# K32W061 register map
Vendor: nxp.com; File version: 1.0
CPU: CM4 r0p1, little endian, MPU, no FPU, VTOR, 3 interrupt priority bits
Registers are 32-bit, read-write, reset 0x0 unless marked. A register's access mark holds for its fields unless they carry their own. Offsets are from the block's base; [hi:lo] are bit positions; {n}, {i} and the like mark numbered series; 'fields as' and 'values as' point back to an identical list.

## SYSCON (part 1 of 2) — This is the description of component syscon. It is the System Control APB bus interface. More details will follow.
Base 0x40000000
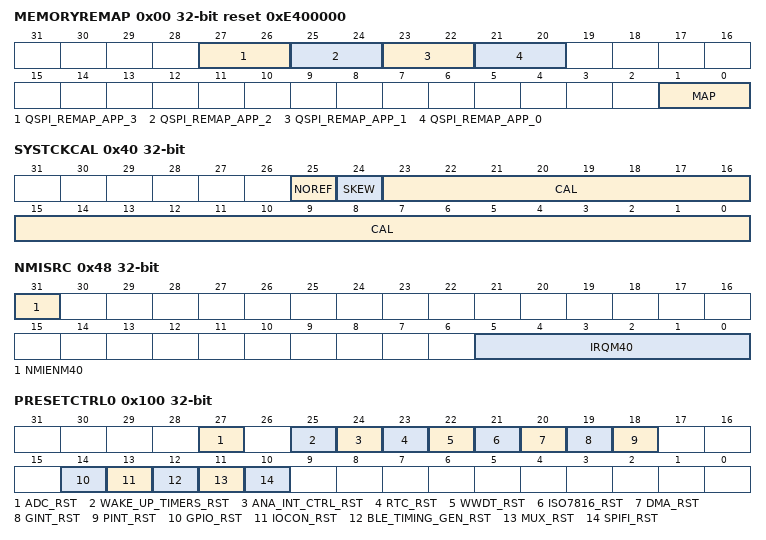
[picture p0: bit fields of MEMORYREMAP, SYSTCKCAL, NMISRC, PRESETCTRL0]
0x00 MEMORYREMAP reset 0xE400000 — Memory Remap control register
  [27:26] QSPI_REMAP_APP_3 — Address bits to use when QSPI Flash address [19:18] = 3 (256-KB unit page). Setting 11 gives no remapping.
  [25:24] QSPI_REMAP_APP_2 — Address bits to use when QSPI Flash address [19:18] = 2 (256-KB unit page). Setting 10 gives no remapping.
  [23:22] QSPI_REMAP_APP_1 — Address bits to use when QSPI Flash address [19:18] = 1 (256-KB unit page). Setting 01 gives no remapping.
  [21:20] QSPI_REMAP_APP_0 — Address bits to use when QSPI Flash address [19:18] = 0 (256-KB unit page). Setting 00 gives no remapping.
  [1:0] MAP — Select the location of the vector table : 0: Vector Table in ROM. 1: Vector Table in RAM. 2: Vector Table in Flash. 3: Vector Table in Flash.
0x10 AHBMATPRIO — AHB Matrix priority control register
0x40 SYSTCKCAL — System tick counter calibration
  [25] NOREF — Cortex System tick timer SYST_CALIB.NOREF setting. When 0, a separate reference clock is available. When 1, a separate reference clock is not available.
  [24] SKEW — Cortex System tick timer SYST_CALIB.SKEW setting. When 0, the value of SYST_CALIB.TENMS field is considered to be precise. When 1, the value of TENMS is not considered to be precise.
  [23:0] CAL — Cortex System tick timer calibration value, readable from Cortex SYST_CALIB.TENMS register field. Set this value to be the number of clock periods to give 10ms period. SYSTICK freq is a function of the mainclk and SYSTICKCLKDIV register. If the tick timer is configured to use the System clock directly then this value must reflect the 10ms tick count for that clock.
0x48 NMISRC — NMI Source Select
  [31] NMIENM40 — Write a 1 to this bit to enable the Non-Maskable Interrupt (NMI) source selected by IRQM40. The NMI Interrupt should be disabled before changing the source selection (IRQM40)
  [5:0] IRQM40 — The number of the interrupt source within the interrupt array that acts as the Non-Maskable Interrupt (NMI) for the Cortex-M4, if enabled by NMIENM40. This can also cause the device to wakeup from sleep.
0x4C ASYNCAPBCTRL — Asynchronous APB Control
  [0] ENABLE — Enables the asynchronous APB bridge and subsystem
0x100 PRESETCTRL0 (PRESETCTRL view) — Peripheral reset control 0
  [27] ADC_RST — ADC reset control. 0: Clear reset to this function. 1: Assert reset to this function.
  [25] WAKE_UP_TIMERS_RST — Wake up Timers reset control. 0: Clear reset to this function. 1: Assert reset to this function. This will clear interrupt status flag. However, configuration for wake timers that is in SYSCON will not be reset, these should be managed through the SYSCON regsiters.
  [24] ANA_INT_CTRL_RST — Analog Modules Interrupt Controller reset control. 0: Clear reset to this function. 1: Assert reset to this function.
  [23] RTC_RST — Real Time Clock (RTC) reset control. 0: Clear reset to this function. 1: Assert reset to this function.
  [22] WWDT_RST — Watchdog Timer reset control. 0: Clear reset to this function. 1: Assert reset to this function.
  [21] ISO7816_RST — ISO7816 reset control. 0: Clear reset to this function. 1: Assert reset to this function.
  [20] DMA_RST — DMA reset control. 0: Clear reset to this function. 1: Assert reset to this function.
  [19] GINT_RST — Group interrupt (GINT) reset control. 0: Clear reset to this function. 1: Assert reset to this function.
  [18] PINT_RST — Pin interrupt (PINT) reset control. 0: Clear reset to this function. 1: Assert reset to this function.
  [14] GPIO_RST — GPIO reset control. 0: Clear reset to this function. 1: Assert reset to this function.
  [13] IOCON_RST — I/O controller reset control. 0: Clear reset to this function. 1: Assert reset to this function.
  [12] BLE_TIMING_GEN_RST — BLE Low Power Control module reset. 0: Clear reset to this function. 1: Assert reset to this function.
  [11] MUX_RST — Input Mux reset control. 0: Clear reset to this function. 1: Assert reset to this function.
  [10] SPIFI_RST — Quad SPI Flash controller reset control. 0: Clear reset to this function. 1: Assert reset to this function.
0x100 PRESETCTRLS0 reset 0xFFFFFFFF (PRESETCTRL view) — Pin assign register
  [31:0] DATA
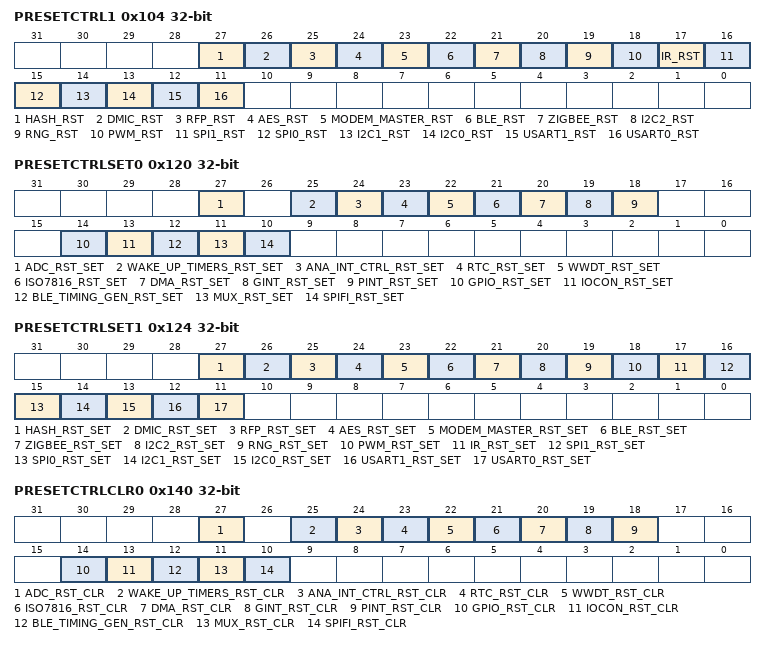
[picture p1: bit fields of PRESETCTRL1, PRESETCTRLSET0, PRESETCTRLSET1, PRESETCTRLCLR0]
0x104 PRESETCTRL1 (PRESETCTRL view) — Peripheral reset control 1
  [27] HASH_RST — HASH reset control. 0: Clear reset to this function. 1: Assert reset to this function.
  [26] DMIC_RST — DMIC Reset control. 0: Clear reset to this function. 1: Assert reset to this function.
  [25] RFP_RST — RFP (Radio controller) reset control. 0: Clear reset to this function. 1: Assert reset to this function.
  [24] AES_RST — AES256 reset control. 0: Clear reset to this function. 1: Assert reset to this function.
  [23] MODEM_MASTER_RST — MODEM AHB Master Interface reset control. 0: Clear reset to this function. 1: Assert reset to this function.
  [22] BLE_RST — BLE reset control. 0: Clear reset to this function. 1: Assert reset to this function.
  [21] ZIGBEE_RST — Zigbee reset control. 0: Clear reset to this function. 1: Assert reset to this function.
  [20] I2C2_RST — I2C2 reset control. 0: Clear reset to this function. 1: Assert reset to this function.
  [19] RNG_RST — Random Number Generator reset control. 0: Clear reset to this function. 1: Assert reset to this function.
  [18] PWM_RST — PWM reset control. 0: Clear reset to this function. 1: Assert reset to this function.
  [17] IR_RST — Infra Red reset control. 0: Clear reset to this function. 1: Assert reset to this function.
  [16] SPI1_RST — SPI1 reset control. 0: Clear reset to this function. 1: Assert reset to this function.
  [15] SPI0_RST — SPI0 reset control. 0: Clear reset to this function. 1: Assert reset to this function.
  [14] I2C1_RST — I2C1 reset control. 0: Clear reset to this function. 1: Assert reset to this function.
  [13] I2C0_RST — I2C0 reset control. 0: Clear reset to this function. 1: Assert reset to this function.
  [12] USART1_RST — UART1 reset control. 0: Clear reset to this function. 1: Assert reset to this function.
  [11] USART0_RST — UART0 reset control. 0: Clear reset to this function. 1: Assert reset to this function.
0x104 PRESETCTRLS1 reset 0xFFFFFFFF (PRESETCTRL view) — Pin assign register
  [31:0] DATA
0x120 PRESETCTRLSET0 reset not defined (PRESETCTRLSET view) — Set bits in PRESETCTRL0. It is recommended that changes to PRESETCTRL registers be accomplished by using the related PRESETCTRLSET and PRESETCTRLCLR registers.
  [27] ADC_RST_SET wo — Writing one to this register sets the ADC_RST bit in the PRESETCTRL0 register
  [25] WAKE_UP_TIMERS_RST_SET wo — Writing one to this register sets the WAKE_UP_TIMERS bit in the PRESETCTRL0 register
  [24] ANA_INT_CTRL_RST_SET wo — Writing one to this register sets the ANA_INT_CTRL_RST bit in the PRESETCTRL0 register
  [23] RTC_RST_SET wo — Writing one to this register sets the RTC_RST bit in the PRESETCTRL0 register
  [22] WWDT_RST_SET wo — Writing one to this register sets the WWDT_RST bit in the PRESETCTRL0 register
  [21] ISO7816_RST_SET wo — Writing one to this register sets the ISO7816_RST bit in the PRESETCTRL0 register
  [20] DMA_RST_SET wo — Writing one to this register sets the DMA_RST bit in the PRESETCTRL0 register
  [19] GINT_RST_SET wo — Writing one to this register sets the GINT_RST bit in the PRESETCTRL0 register
  [18] PINT_RST_SET wo — Writing one to this register sets the PINT_RST bit in the PRESETCTRL0 register
  [14] GPIO_RST_SET wo — Writing one to this register sets the GPIO_RST bit in the PRESETCTRL0 register
  [13] IOCON_RST_SET wo — Writing one to this register sets the IOCON_RST bit in the PRESETCTRL0 register
  [12] BLE_TIMING_GEN_RST_SET wo — Writing one to this register sets the BLE_TIMING_GEN_RST bit in the PRESETCTRL0 register
  [11] MUX_RST_SET wo — Writing one to this register sets the MUX_RST bit in the PRESETCTRL0 register
  [10] SPIFI_RST_SET wo — Writing one to this register sets the SPIFI_RST bit in the PRESETCTRL0 register
0x120 PRESETCTRLSETS0 reset 0xFFFFFFFF (PRESETCTRLSET view) — Pin assign register
  [31:0] DATA
0x124 PRESETCTRLSET1 reset not defined (PRESETCTRLSET view) — Set bits in PRESETCTRL1. It is recommended that changes to PRESETCTRL registers be accomplished by using the related PRESETCTRLSET and PRESETCTRLCLR registers.
  [27] HASH_RST_SET wo — Writing one to this register sets the HASH_RST bit in the PRESETCTRL1 register
  [26] DMIC_RST_SET wo — Writing one to this register sets the DMIC_RST bit in the PRESETCTRL1 register
  [25] RFP_RST_SET wo — Writing one to this register sets the RFP_RST bit in the PRESETCTRL1 register
  [24] AES_RST_SET wo — Writing one to this register sets the AES_RST bit in the PRESETCTRL1 register
  [23] MODEM_MASTER_RST_SET wo — Writing one to this register sets the MODEM_MASTER_RST bit in the PRESETCTRL1 register
  [22] BLE_RST_SET wo — Writing one to this register sets the BLE_RST bit in the PRESETCTRL1 register
  [21] ZIGBEE_RST_SET wo — Writing one to this register sets the ZIGBEE_RST bit in the PRESETCTRL1 register
  [20] I2C2_RST_SET wo — Writing one to this register sets the I2C2_RST bit in the PRESETCTRL1 register
  [19] RNG_RST_SET wo — Writing one to this register sets the RNG_RST bit in the PRESETCTRL1 register
  [18] PWM_RST_SET wo — Writing one to this register sets the PWM_RST bit in the PRESETCTRL1 register
  [17] IR_RST_SET wo — Writing one to this register sets the IR_RST bit in the PRESETCTRL1 register
  [16] SPI1_RST_SET wo — Writing one to this register sets the SPI1_RST bit in the PRESETCTRL1 register
  [15] SPI0_RST_SET wo — Writing one to this register sets the SPI0_RST bit in the PRESETCTRL1 register
  [14] I2C1_RST_SET wo — Writing one to this register sets the I2C1_RST bit in the PRESETCTRL1 register
  [13] I2C0_RST_SET wo — Writing one to this register sets the I2C0_RST bit in the PRESETCTRL1 register
  [12] USART1_RST_SET wo — Writing one to this register sets the UART1_RST bit in the PRESETCTRL1 register
  [11] USART0_RST_SET wo — Writing one to this register sets the UART0_RST bit in the PRESETCTRL1 register
0x124 PRESETCTRLSETS1 reset 0xFFFFFFFF (PRESETCTRLSET view) — Pin assign register
  [31:0] DATA
0x140 PRESETCTRLCLR0 reset not defined (PRESETCTRLCLR view) — Clear bits in PRESETCTRL0. It is recommended that changes to PRESETCTRL registers be accomplished by using the related PRESETCTRLSET and PRESETCTRLCLR registers.
  [27] ADC_RST_CLR wo — Writing one to this register clears the ADC_RST bit in the PRESETCTRL0 register
  [25] WAKE_UP_TIMERS_RST_CLR wo — Writing one to this register clears the WAKE_UP_TIMERS_RST bit in the PRESETCTRL0 register
  [24] ANA_INT_CTRL_RST_CLR wo — Writing one to this register clears the ANA_INT_CTRL_RST bit in the PRESETCTRL0 register
  [23] RTC_RST_CLR wo — Writing one to this register clears the RTC_RST bit in the PRESETCTRL0 register
  [22] WWDT_RST_CLR wo — Writing one to this register clears the WWDT_RST bit in the PRESETCTRL0 register
  [21] ISO7816_RST_CLR wo — Writing one to this register clears the ISO7816_RST bit in the PRESETCTRL0 register
  [20] DMA_RST_CLR wo — Writing one to this register clears the DMA_RST bit in the PRESETCTRL0 register
  [19] GINT_RST_CLR wo — Writing one to this register clears the GINT_RST bit in the PRESETCTRL0 register
  [18] PINT_RST_CLR wo — Writing one to this register clears the PINT_RST bit in the PRESETCTRL0 register
  [14] GPIO_RST_CLR wo — Writing one to this register clears the GPIO_RST bit in the PRESETCTRL0 register
  [13] IOCON_RST_CLR wo — Writing one to this register clears the IOCON_RST bit in the PRESETCTRL0 register
  [12] BLE_TIMING_GEN_RST_CLR wo — Writing one to this register clears the BLE_TIMING_GEN_RST bit in the PRESETCTRL0 register
  [11] MUX_RST_CLR wo — Writing one to this register clears the MUX_RST bit in the PRESETCTRL0 register
  [10] SPIFI_RST_CLR wo — Writing one to this register clears the SPIFI_RST bit in the PRESETCTRL0 register
0x140 PRESETCTRLCLRS0 reset 0xFFFFFFFF (PRESETCTRLCLR view) — Pin assign register
  [31:0] DATA
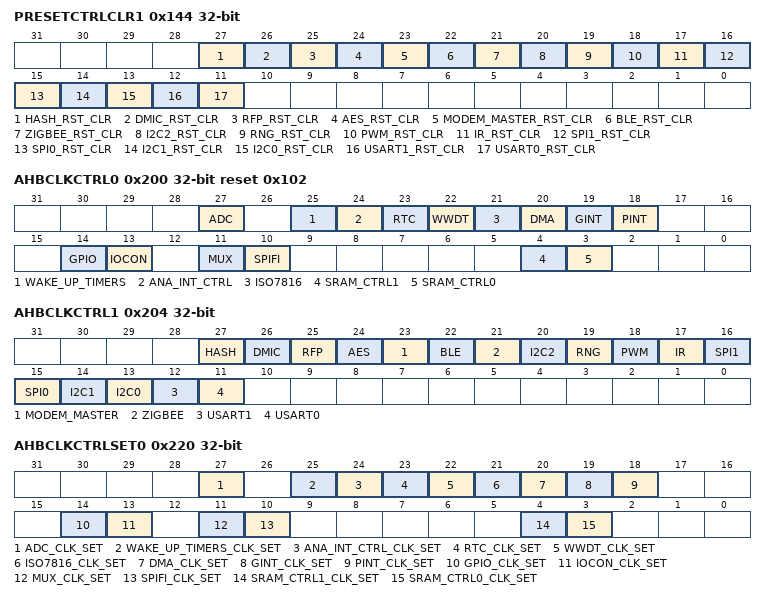
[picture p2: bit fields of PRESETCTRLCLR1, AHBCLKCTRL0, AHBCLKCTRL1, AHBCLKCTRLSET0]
0x144 PRESETCTRLCLR1 reset not defined (PRESETCTRLCLR view) — Clear bits in PRESETCTRL1. It is recommended that changes to PRESETCTRL registers be accomplished by using the related PRESETCTRLSET and PRESETCTRLCLR registers.
  [27] HASH_RST_CLR wo — Writing one to this register clears the HASH_RST bit in the PRESETCTRL1 register
  [26] DMIC_RST_CLR wo — Writing one to this register clears the DMIC_RST bit in the PRESETCTRL1 register
  [25] RFP_RST_CLR wo — Writing one to this register clears the RFP_RST bit in the PRESETCTRL1 register
  [24] AES_RST_CLR wo — Writing one to this register clears the AES_RST bit in the PRESETCTRL1 register
  [23] MODEM_MASTER_RST_CLR wo — Writing one to this register clears the MODEM_MASTER_RST bit in the PRESETCTRL1 register
  [22] BLE_RST_CLR wo — Writing one to this register clears the BLE_RST bit in the PRESETCTRL1 register
  [21] ZIGBEE_RST_CLR wo — Writing one to this register clears the ZIGBEE_RST bit in the PRESETCTRL1 register
  [20] I2C2_RST_CLR wo — Writing one to this register clears the I2C2_RST bit in the PRESETCTRL1 register
  [19] RNG_RST_CLR wo — Writing one to this register clears the RNG_RST bit in the PRESETCTRL1 register
  [18] PWM_RST_CLR wo — Writing one to this register clears the PWM_RST bit in the PRESETCTRL1 register
  [17] IR_RST_CLR wo — Writing one to this register clears the IR_RST bit in the PRESETCTRL1 register
  [16] SPI1_RST_CLR wo — Writing one to this register clears the SPI1_RST bit in the PRESETCTRL1 register
  [15] SPI0_RST_CLR wo — Writing one to this register clears the SPI0_RST bit in the PRESETCTRL1 register
  [14] I2C1_RST_CLR wo — Writing one to this register clears the I2C1_RST bit in the PRESETCTRL1 register
  [13] I2C0_RST_CLR wo — Writing one to this register clears the I2C0_RST bit in the PRESETCTRL1 register
  [12] USART1_RST_CLR wo — Writing one to this register clears the UART1_RST bit in the PRESETCTRL1 register
  [11] USART0_RST_CLR wo — Writing one to this register clears the UART0_RST bit in the PRESETCTRL1 register
0x144 PRESETCTRLCLRS1 reset 0xFFFFFFFF (PRESETCTRLCLR view) — Pin assign register
  [31:0] DATA
0x200 AHBCLKCTRL0 reset 0x102 (AHBCLKCTRL view) — AHB Clock control 0
  [27] ADC — Enables the clock for the ADC Controller. 0: Disable. 1: Enable.
  [25] WAKE_UP_TIMERS — Enables the clock for the Wake up Timers. 0: Disable. 1: Enable.
  [24] ANA_INT_CTRL — Enables the clock for the Analog Interrupt Control module (for BOD and comparator status and interrupt control). 0: Disable. 1: Enable.
  [23] RTC — Enables the clock for the RTC. 0: Disable. 1: Enable.
  [22] WWDT — Enables the clock for the Watchdog Timer. 0: Disable. 1: Enable.
  [21] ISO7816 — Enables the clock for the ISO7816 smart card interface. 0: Disable. 1: Enable.
  [20] DMA — Enables the clock for the DMA controller. 0: Disable. 1: Enable.
  [19] GINT — Enables the clock for the Group interrupt block (GINT). 0: Disable. 1: Enable.
  [18] PINT — Enables the clock for the Pin interrupt block (PINT). 0: Disable. 1: Enable.
  [14] GPIO — Enables the clock for the GPIO. 0: Disable. 1: Enable.
  [13] IOCON — Enables the clock for the I/O controller block. 0: Disable. 1: Enable.
  [11] MUX — Enables the clock for the Input Mux. 0: Disable. 1: Enable.
  [10] SPIFI — Enables the clock for the Quad SPI Flash controller [Note: SPIFI IOs need configuring for high drive]. 0: Disable. 1: Enable.
  [4] SRAM_CTRL1 — Enables the clock for the SRAM Controller 1 (SRAM 8 to SRAM 11). 0: Disable. 1: Enable.
  [3] SRAM_CTRL0 — Enables the clock for the SRAM Controller 0 (SRAM 0 to SRAM 7). 0: Disable. 1: Enable.
0x200 AHBCLKCTRLS0 reset 0xFFFFFFFF (AHBCLKCTRL view) — Pin assign register
  [31:0] DATA
0x204 AHBCLKCTRL1 (AHBCLKCTRL view) — AHB Clock control 1
  [27] HASH — Enable the clock for the Hash. 0: Disable. 1: Enable.
  [26] DMIC — Enable the clock for the DMIC. 0: Disable. 1: Enable.
  [25] RFP — Enable the clock for the RFP (Radio Front End controller). 0: Disable. 1: Enable.
  [24] AES — Enable the clock for the AES. 0: Disable. 1: Enable.
  [23] MODEM_MASTER — Enable the clock for the Modem AHB Master Interface. 0: Disable. 1: Enable.
  [22] BLE — Enable the clock for the BLE Modem. 0: Disable. 1: Enable.
  [21] ZIGBEE — Enable the clock for the Zigbee Modem . 0: Disable. 1: Enable.
  [20] I2C2 — Enable the clock for the I2C2. 0: Disable. 1: Enable.
  [19] RNG — Enable the clock for the Random Number Generator. 0: Disable. 1: Enable.
  [18] PWM — Enable the clock for the PWM. 0: Disable. 1: Enable.
  [17] IR — Enable the clock for the Infra Red. 0: Disable. 1: Enable.
  [16] SPI1 — Enable the clock for the SPI1. 0: Disable. 1: Enable.
  [15] SPI0 — Enable the clock for the SPI0. 0: Disable. 1: Enable.
  [14] I2C1 — Enable the clock for the I2C1. 0: Disable. 1: Enable.
  [13] I2C0 — Enable the clock for the I2C0. 0: Disable. 1: Enable.
  [12] USART1 — Enable the clock for the UART1. 0: Disable. 1: Enable.
  [11] USART0 — Enable the clock for the UART0. 0: Disable. 1: Enable.
0x204 AHBCLKCTRLS1 reset 0xFFFFFFFF (AHBCLKCTRL view) — Pin assign register
  [31:0] DATA
0x220 AHBCLKCTRLSET0 reset not defined (AHBCLKCTRLSET view) — Set bits in AHBCLKCTRL0
  [27] ADC_CLK_SET wo — Writing one to this register sets the ADC bit in the AHBCLKCTRL0 register.
  [25] WAKE_UP_TIMERS_CLK_SET wo — Writing one to this register sets the WAKE_UP_TIMERS bit in the AHBCLKCTRL0 register.
  [24] ANA_INT_CTRL_CLK_SET wo — Writing one to this register sets the ANA_INT_CTRL bit in the AHBCLKCTRL0 register.
  [23] RTC_CLK_SET wo — Writing one to this register sets the RTC bit in the AHBCLKCTRL0 register.
  [22] WWDT_CLK_SET wo — Writing one to this register sets the WWDT bit in the AHBCLKCTRL0 register.
  [21] ISO7816_CLK_SET wo — Writing one to this register sets the ISO7816 bit in the AHBCLKCTRL0 register.
  [20] DMA_CLK_SET wo — Writing one to this register sets the DMA bit in the AHBCLKCTRL0 register.
  [19] GINT_CLK_SET wo — Writing one to this register sets the GINT bit in the AHBCLKCTRL0 register.
  [18] PINT_CLK_SET wo — Writing one to this register sets the PINT bit in the AHBCLKCTRL0 register.
  [14] GPIO_CLK_SET wo — Writing one to this register sets the GPIO bit in the AHBCLKCTRL0 register.
  [13] IOCON_CLK_SET wo — Writing one to this register sets the IOCON bit in the AHBCLKCTRL0 register.
  [11] MUX_CLK_SET wo — Writing one to this register sets the MUX bit in the AHBCLKCTRL0 register.
  [10] SPIFI_CLK_SET wo — Writing one to this register sets the SPIFI bit in the AHBCLKCTRL0 register.
  [4] SRAM_CTRL1_CLK_SET wo — Writing one to this register sets the SRAM_CTRL1 bit in the AHBCLKCTRL0 register.
  [3] SRAM_CTRL0_CLK_SET wo — Writing one to this register sets the SRAM_CTRL0 bit in the AHBCLKCTRL0 register.
0x220 AHBCLKCTRLSETS0 reset 0xFFFFFFFF (AHBCLKCTRLSET view) — Pin assign register
  [31:0] DATA
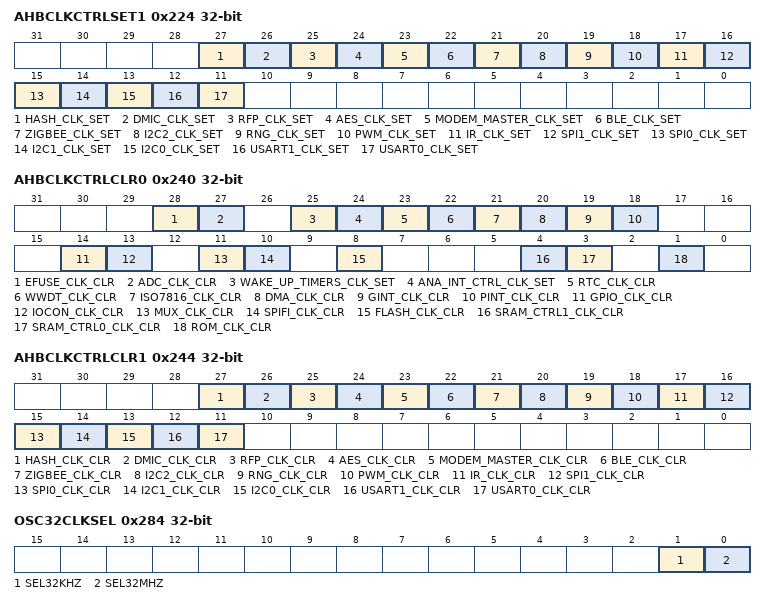
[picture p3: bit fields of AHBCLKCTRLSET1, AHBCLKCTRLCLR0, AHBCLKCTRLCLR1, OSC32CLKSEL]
0x224 AHBCLKCTRLSET1 reset not defined (AHBCLKCTRLSET view) — Set bits in AHBCLKCTRL1
  [27] HASH_CLK_SET wo — Writing one to this register sets the HASH bit in the AHBCLKCTRL1 register.
  [26] DMIC_CLK_SET wo — Writing one to this register sets the DMIC bit in the AHBCLKCTRL1 register.
  [25] RFP_CLK_SET wo — Writing one to this register sets the RFP bit in the AHBCLKCTRL1 register.
  [24] AES_CLK_SET wo — Writing one to this register sets the AES bit in the AHBCLKCTRL1 register.
  [23] MODEM_MASTER_CLK_SET wo — Writing one to this register sets the MODEM_MASTER bit in the AHBCLKCTRL1 register.
  [22] BLE_CLK_SET wo — Writing one to this register sets the BLE bit in the AHBCLKCTRL1 register.
  [21] ZIGBEE_CLK_SET wo — Writing one to this register sets the ZIGBEE bit in the AHBCLKCTRL1 register.
  [20] I2C2_CLK_SET wo — Writing one to this register sets the I2C2 bit in the AHBCLKCTRL1 register.
  [19] RNG_CLK_SET wo — Writing one to this register sets the RNG bit in the AHBCLKCTRL1 register.
  [18] PWM_CLK_SET wo — Writing one to this register sets the PWM bit in the AHBCLKCTRL1 register.
  [17] IR_CLK_SET wo — Writing one to this register sets the IR bit in the AHBCLKCTRL1 register.
  [16] SPI1_CLK_SET wo — Writing one to this register sets the SPI1 bit in the AHBCLKCTRL1 register.
  [15] SPI0_CLK_SET wo — Writing one to this register sets the SPI0 bit in the AHBCLKCTRL1 register.
  [14] I2C1_CLK_SET wo — Writing one to this register sets the I2C1 bit in the AHBCLKCTRL1 register.
  [13] I2C0_CLK_SET wo — Writing one to this register sets the I2C0 bit in the AHBCLKCTRL1 register.
  [12] USART1_CLK_SET wo — Writing one to this register sets the UART1 bit in the AHBCLKCTRL1 register.
  [11] USART0_CLK_SET wo — Writing one to this register sets the UART0 bit in the AHBCLKCTRL1 register.
0x224 AHBCLKCTRLSETS1 reset 0xFFFFFFFF (AHBCLKCTRLSET view) — Pin assign register
  [31:0] DATA
0x240 AHBCLKCTRLCLR0 reset not defined (AHBCLKCTRLCLR view) — Clear bits in AHBCLKCTRL0
  [28] EFUSE_CLK_CLR wo — Writing one to this register clears the EFUSE bit in the AHBCLKCTRL0 register.
  [27] ADC_CLK_CLR wo — Writing one to this register clears the ADC bit in the AHBCLKCTRL0 register.
  [25] WAKE_UP_TIMERS_CLK_SET wo — Writing one to this register clears the WAKE_UP_TIMERS bit in the AHBCLKCTRL0 register.
  [24] ANA_INT_CTRL_CLK_SET wo — Writing one to this register clears the ANA_INT_CTRL bit in the AHBCLKCTRL0 register.
  [23] RTC_CLK_CLR wo — Writing one to this register clears the RTC bit in the AHBCLKCTRL0 register.
  [22] WWDT_CLK_CLR wo — Writing one to this register clears the WWDT bit in the AHBCLKCTRL0 register.
  [21] ISO7816_CLK_CLR wo — Writing one to this register clears the ISO7816 bit in the AHBCLKCTRL0 register.
  [20] DMA_CLK_CLR wo — Writing one to this register clears the DMA bit in the AHBCLKCTRL0 register.
  [19] GINT_CLK_CLR wo — Writing one to this register clears the GINT bit in the AHBCLKCTRL0 register.
  [18] PINT_CLK_CLR wo — Writing one to this register clears the PINT bit in the AHBCLKCTRL0 register.
  [14] GPIO_CLK_CLR wo — Writing one to this register clears the GPIO bit in the AHBCLKCTRL0 register.
  [13] IOCON_CLK_CLR wo — Writing one to this register clears the IOCON bit in the AHBCLKCTRL0 register.
  [11] MUX_CLK_CLR wo — Writing one to this register clears the MUX bit in the AHBCLKCTRL0 register.
  [10] SPIFI_CLK_CLR wo — Writing one to this register clears the SPIFI bit in the AHBCLKCTRL0 register.
  [8] FLASH_CLK_CLR wo — Writing one to this register clears the FLASH bit in the AHBCLKCTRL0 register.
  [4] SRAM_CTRL1_CLK_CLR wo — Writing one to this register clears the SRAM_CTRL1 bit in the AHBCLKCTRL0 register.
  [3] SRAM_CTRL0_CLK_CLR wo — Writing one to this register clears the SRAM_CTRL0 bit in the AHBCLKCTRL0 register.
  [1] ROM_CLK_CLR wo — Writing one to this register clears the ROM bit in the AHBCLKCTRL0 register.
0x240 AHBCLKCTRLCLRS0 reset 0xFFFFFFFF (AHBCLKCTRLCLR view) — Pin assign register
  [31:0] DATA
0x244 AHBCLKCTRLCLR1 reset not defined (AHBCLKCTRLCLR view) — Clear bits in AHBCLKCTRL1
  [27] HASH_CLK_CLR wo — Writing one to this register clears the HASH bit in the AHBCLKCTRL1 register.
  [26] DMIC_CLK_CLR wo — Writing one to this register clears the DMIC bit in the AHBCLKCTRL1 register.
  [25] RFP_CLK_CLR wo — Writing one to this register clears the RFP bit in the AHBCLKCTRL1 register.
  [24] AES_CLK_CLR wo — Writing one to this register clears the AES bit in the AHBCLKCTRL1 register.
  [23] MODEM_MASTER_CLK_CLR wo — Writing one to this register clears the MODEM_MASTER bit in the AHBCLKCTRL1 register.
  [22] BLE_CLK_CLR wo — Writing one to this register clears the BLE bit in the AHBCLKCTRL1 register.
  [21] ZIGBEE_CLK_CLR wo — Writing one to this register clears the ZIGBEE bit in the AHBCLKCTRL1 register.
  [20] I2C2_CLK_CLR wo — Writing one to this register clears the I2C2 bit in the AHBCLKCTRL1 register.
  [19] RNG_CLK_CLR wo — Writing one to this register clears the RNG bit in the AHBCLKCTRL1 register.
  [18] PWM_CLK_CLR wo — Writing one to this register clears the PWM bit in the AHBCLKCTRL1 register.
  [17] IR_CLK_CLR wo — Writing one to this register clears the IR bit in the AHBCLKCTRL1 register.
  [16] SPI1_CLK_CLR wo — Writing one to this register clears the SPI1 bit in the AHBCLKCTRL1 register.
  [15] SPI0_CLK_CLR wo — Writing one to this register clears the SPI0 bit in the AHBCLKCTRL1 register.
  [14] I2C1_CLK_CLR wo — Writing one to this register clears the I2C1 bit in the AHBCLKCTRL1 register.
  [13] I2C0_CLK_CLR wo — Writing one to this register clears the I2C0 bit in the AHBCLKCTRL1 register.
  [12] USART1_CLK_CLR wo — Writing one to this register clears the UART1 bit in the AHBCLKCTRL1 register.
  [11] USART0_CLK_CLR wo — Writing one to this register clears the UART0 bit in the AHBCLKCTRL1 register.
0x244 AHBCLKCTRLCLRS1 reset 0xFFFFFFFF (AHBCLKCTRLCLR view) — Pin assign register
  [31:0] DATA
0x280 MAINCLKSEL — Main clock source select
  [2:0] SEL — Main clock source selection:
    0=FRO12M (12 MHz free running oscillator (FRO)); 2=XTAL32M (32 MHz crystal oscillator (XTAL)); 3=FRO32M (32 MHz free running oscillator (FRO)); 4=FRO48M (48 MHz free running oscillator (FRO))
0x284 OSC32CLKSEL — OSC32KCLK and OSC32MCLK clock sources select. Note: this register is not locked by CLOCKGENUPDATELOCKOUT
  [1] SEL32KHZ — OSC32KCLK clock source selection
    0=FRO32K (32 KHz free running oscillator (FRO)); 1=XTAL32K (32 KHz crystal oscillator)
  [0] SEL32MHZ — OSC32MCLK clock source selection
    0=FRO32M (32 MHz free running oscillator (FRO)); 1=XTAL32M (32 MHz crystal oscillator)
0x288 CLKOUTSEL reset 0x7 — CLKOUT clock source select
  [2:0] SEL — CLKOUT clock source selection
    0=MAINCLK (CPU & System Bus clock); 1=XTAL32K (32 KHz crystal oscillator (XTAL)); 2=FRO32K (32 KHz free running oscillator (FRO)); 3=XTAL32M (32 MHz crystal oscillator (XTAL)); 5=FRO48M (48 MHz free running oscillator (FRO)); 6=FRO1M (1 MHz free running oscillator (FRO)); 7=TESTCLK (No clock)
0x2A0 SPIFICLKSEL reset 0x7 — SPIFI clock source select
  [2:0] SEL — SPIFICLK clock source selection
    0=MAINCLK (CPU & System Bus clock); 1=XTAL32M (32 MHz crystal oscillator (XTAL)); {v}=TESTCLK{v-2} (No clock) (v=2..7)
0x2A4 ADCCLKSEL reset 0x3 — ADC clock source select
  [1:0] SEL — ADCCLK clock source selection
    0=XTAL32M (32 MHz crystal oscillator (XTAL)); 1=FRO12M (FRO 12 MHz); 3=TESTCLK (No clock)
0x2B0 USARTCLKSEL reset 0x3 — USART0 & 1 clock source select
  [1:0] SEL — USARTCLK (USART0 & 1) clock source selection
    0=OSC32MCLK (Either 32 MHz FRO or 32 MHz XTAL (see OSC32CLKSEL)); 1=FRO48M (48 MHz free running oscillator (FRO)); 2=FRGCLK (Fractional Rate Generator clock (see FRGCLKSEL)); 3=TESTCLK (No clock)
0x2B4 I2CCLKSEL reset 0x3 — I2C0, 1 and 2 clock source select
  [1:0] SEL — I2CCLK (I2C0 & 1) clock source selection
    0=OSC32MCLK (Either 32 MHz FRO or 32 MHz XTAL (see OSC32CLKSEL)); 1=FRO48M (48 MHz free running oscillator (FRO)); 3=TESTCLK (No clock)
0x2B8 SPICLKSEL reset 0x3 — SPI0 & 1 clock source select
  [1:0] SEL — SPICLK (SPI0 & 1) clock source selection
    values as I2CCLKSEL.SEL
0x2BC IRCLKSEL reset 0x3 — Infra Red clock source select
  [1:0] SEL — IRCLK (IR Blaster) clock source selection
    values as I2CCLKSEL.SEL
0x2C0 PWMCLKSEL reset 0x3 — PWM clock source select
  [1:0] SEL — PWMCLK (PWM) clock source selection
    0=OSC32MCLK (Either 32 MHz FRO or 32 MHz XTAL (see OSC32CLKSEL)); 1=FRO48M (48 MHz free running oscillator (FRO)); 3=TESTCLK (No Clock)
0x2C4 WDTCLKSEL reset 0x3 — Watchdog Timer clock source select
  [1:0] SEL — WDTCLK (Watchdog Timer) clock source selection
    0=OSC32MCLK (Either 32 MHz FRO or 32 MHz XTAL (see OSC32CLKSEL)); 1=OSC32KCLK (Either 32 KHz FRO or 32 KHz XTAL (see OSC32CLKSEL)); 2=FRO1M (1 MHz FRO); 3=TESTCLK (No Clock)
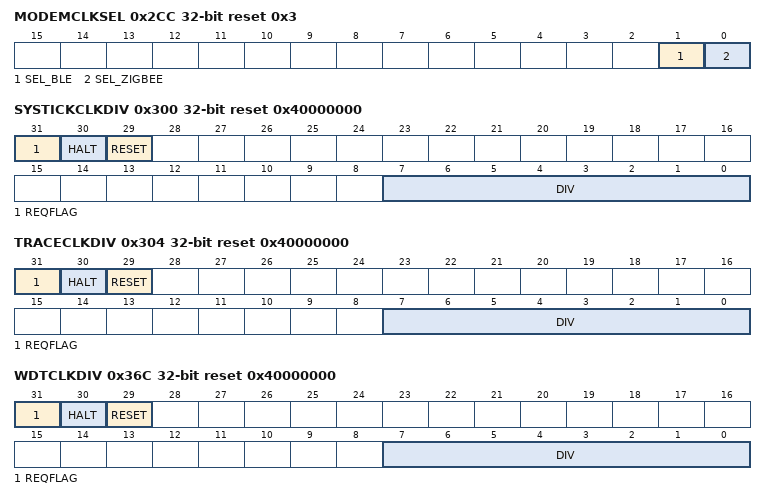
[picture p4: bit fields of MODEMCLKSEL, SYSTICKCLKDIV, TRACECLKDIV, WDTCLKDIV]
0x2CC MODEMCLKSEL reset 0x3 — Modem clock source select
  [1] SEL_BLE — BLE 32 MHz clock source selection
    0=XTAL32M (32 MHz XTAL); 1=TESTCLK (No Clock)
  [0] SEL_ZIGBEE — Zigbee Modem clock source selection
    0=XTAL32M (32 MHz XTAL); 1=TESTCLK (No Clock)
0x2E8 FRGCLKSEL reset 0x3 — Fractional Rate Generator (FRG) clock source select. The FRG is one of the USART clocking options.
  [1:0] SEL — Fractional Rate Generator clock source selection
    0=MAINCLK (System Bus clock); 1=OSC32MCLK (Either 32 MHz FRO or 32 MHz XTAL (see OSC32CLKSEL)); 2=FRO48M (48 MHz free running oscillator (FRO)); 3=TESTCLK (No Clock)
0x2EC DMICCLKSEL reset 0x7 — Digital microphone (DMIC) subsystem clock select
  [2:0] SEL — DMIC clock source selection
    0=MAINCLK (System Bus clock); 1=OSC32KCLK (Either 32 KHz FRO or 32 KHz XTAL (see OSC32CLKSEL)); 2=FRO48M (48 MHz free running oscillator (FRO)); 3=MCLK (External clock); 4=FRO1M (1 MHz free running oscillator (FRO)); 5=FRO12M (12 MHz free running oscillator (FRO)); 7=TESTCLK (No Clock)
0x2F0 WKTCLKSEL reset 0x3 — Wake-up Timer clock select
  [1:0] SEL — Wake-up Timers clock source selection
    0=OSC32KCLK (Either 32 KHz FRO or 32 KHz XTAL (see OSC32CLKSEL)); 3=TESTCLK (No Clock)
0x300 SYSTICKCLKDIV reset 0x40000000 — SYSTICK clock divider. The SYSTICK clock can drive the SYSTICK function within the processor.
  [31] REQFLAG ro — Divider status flag. Set when a change is made to the divider value, cleared when the change is complete.
  [30] HALT — Halts the divider counter. The intent is to allow the divider s clock source to be changed without the risk of a glitch at the output.
  [29] RESET — Resets the divider counter. Can be used to make sure a new divider value is used right away rather than completing the previous count.
  [7:0] DIV — Clock divider setting, divider ratio is (DIV+1). E.g. 0: Divide by 1 and 255: Divide by 256.
0x304 TRACECLKDIV reset 0x40000000 — TRACE clock divider, used for part of the Serial debugger (SWD) feature.
  fields as SYSTICKCLKDIV
0x36C WDTCLKDIV reset 0x40000000 — Watchdog Timer clock divider
  fields as SYSTICKCLKDIV
